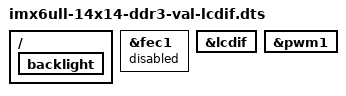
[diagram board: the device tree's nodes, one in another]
/*
 * Copyright (C) 2016 Freescale Semiconductor, Inc.
 *
 * This program is free software; you can redistribute it and/or modify
 * it under the terms of the GNU General Public License version 2 as
 * published by the Free Software Foundation.
 */

/* DTS file for LCDIF at imx6ull ddr3 val board */

#include "imx6ull-14x14-ddr3-val.dts"

/ {
	backlight {
		status = "okay";
	};
};

&fec1 {
	status = "disabled";
};

&lcdif {
	status = "okay";
};

&pwm1 {
	status = "okay";
};
